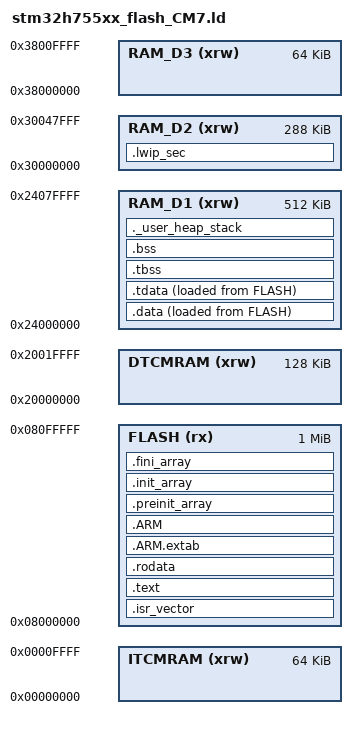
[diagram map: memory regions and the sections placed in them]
/*
******************************************************************************
**
**  File        : LinkerScript.ld
**
**  Abstract    : Linker script for STM32H755 (Cortex-M7)
**                1024Kbytes FLASH and correct RAM mapping for Ethernet
**
**  Target      : STMicroelectronics STM32H755ZIT6
**
******************************************************************************
*/

/* Entry Point */
ENTRY(Reset_Handler)

/* Specify the memory areas */
MEMORY
{
  DTCMRAM (xrw)  : ORIGIN = 0x20000000, LENGTH = 128K
  ITCMRAM (xrw)  : ORIGIN = 0x00000000, LENGTH = 64K
  RAM_D1 (xrw)   : ORIGIN = 0x24000000, LENGTH = 512K  /* AXI SRAM */
  RAM_D2 (xrw)   : ORIGIN = 0x30000000, LENGTH = 288K  /* AHB SRAM (for Ethernet DMA) */
  RAM_D3 (xrw)   : ORIGIN = 0x38000000, LENGTH = 64K   /* AHB SRAM 4 */
  FLASH (rx)     : ORIGIN = 0x08000000, LENGTH = 1024K
}

/* Highest address of the user mode stack */
_estack = 0x20020000;    /* end of DTCMRAM */

/* Generate a link error if heap and stack don't fit into RAM */
_Min_Heap_Size = 0x10000;    /* newlib heap for micro-ROS/newlib runtime */
_Min_Stack_Size = 0x2000;    /* MSP headroom during early boot and faults */

/* Define output sections */
SECTIONS
{
  /* The startup code goes first into FLASH */
  .isr_vector :
  {
    . = ALIGN(4);
    KEEP(*(.isr_vector)) /* Startup code */
    . = ALIGN(4);
  } >FLASH

  /* The program code and other data goes into FLASH */
  .text :
  {
    . = ALIGN(4);
    *(.text)           /* .text sections (code) */
    *(.text*)          /* .text* sections (code) */
    *(.glue_7)         /* glue arm to thumb code */
    *(.glue_7t)        /* glue thumb to arm code */
    *(.eh_frame)

    KEEP (*(.init))
    KEEP (*(.fini))

    . = ALIGN(4);
    _etext = .;        /* define a global symbols at end of code */
  } >FLASH

  /* Constant data goes into FLASH */
  .rodata :
  {
    . = ALIGN(4);
    *(.rodata)         /* .rodata sections (constants, strings, etc.) */
    *(.rodata*)        /* .rodata* sections (constants, strings, etc.) */
    . = ALIGN(4);
  } >FLASH

  .ARM.extab (READONLY) : /* The READONLY keyword is only supported in GCC11 and later, remove it if using GCC10 or earlier. */
  {
    . = ALIGN(4);
    *(.ARM.extab* .gnu.linkonce.armextab.*)
    . = ALIGN(4);
  } >FLASH

  .ARM (READONLY) : /* The READONLY keyword is only supported in GCC11 and later, remove it if using GCC10 or earlier. */
  {
    . = ALIGN(4);
    __exidx_start = .;
    *(.ARM.exidx*)
    __exidx_end = .;
    . = ALIGN(4);
  } >FLASH

  .preinit_array (READONLY) : /* The READONLY keyword is only supported in GCC11 and later, remove it if using GCC10 or earlier. */
  {
    . = ALIGN(4);
    PROVIDE_HIDDEN (__preinit_array_start = .);
    KEEP (*(.preinit_array*))
    PROVIDE_HIDDEN (__preinit_array_end = .);
    . = ALIGN(4);
  } >FLASH

  .init_array (READONLY) : /* The READONLY keyword is only supported in GCC11 and later, remove it if using GCC10 or earlier. */
  {
    . = ALIGN(4);
    PROVIDE_HIDDEN (__init_array_start = .);
    KEEP (*(SORT(.init_array.*)))
    KEEP (*(.init_array*))
    PROVIDE_HIDDEN (__init_array_end = .);
    . = ALIGN(4);
  } >FLASH

  .fini_array (READONLY) : /* The READONLY keyword is only supported in GCC11 and later, remove it if using GCC10 or earlier. */
  {
    . = ALIGN(4);
    PROVIDE_HIDDEN (__fini_array_start = .);
    KEEP (*(SORT(.fini_array.*)))
    KEEP (*(.fini_array*))
    PROVIDE_HIDDEN (__fini_array_end = .);
    . = ALIGN(4);
  } >FLASH

  /* used by the startup to initialize data */
  _sidata = LOADADDR(.data);

  /* Initialized data sections goes into RAM, load LMA copy after code */
  .data :
  {
    . = ALIGN(4);
    _sdata = .;        /* create a global symbol at data start */
    *(.data)           /* .data sections */
    *(.data*)          /* .data* sections */
    . = ALIGN(4);
  } >RAM_D1 AT> FLASH

  /* Initialized TLS data section */
  .tdata : ALIGN(4)
  {
    *(.tdata .tdata.* .gnu.linkonce.td.*)
    . = ALIGN(4);
    _edata = .;        /* define a global symbol at data end */
    PROVIDE(__data_end = .);
    PROVIDE(__tdata_end = .);
  } >RAM_D1 AT> FLASH

  PROVIDE( __tdata_start = ADDR(.tdata) );
  PROVIDE( __tdata_size = __tdata_end - __tdata_start );

  PROVIDE( __data_start = ADDR(.data) );
  PROVIDE( __data_size = __data_end - __data_start );

  PROVIDE( __tdata_source = LOADADDR(.tdata) );
  PROVIDE( __tdata_source_end = LOADADDR(.tdata) + SIZEOF(.tdata) );
  PROVIDE( __tdata_source_size = __tdata_source_end - __tdata_source );

  PROVIDE( __data_source = LOADADDR(.data) );
  PROVIDE( __data_source_end = __tdata_source_end );
  PROVIDE( __data_source_size = __data_source_end - __data_source );

  /* Uninitialized TLS data section */
  .tbss (NOLOAD) : ALIGN(4)
  {
    _sbss = .;         /* define a global symbol at bss start */
    __bss_start__ = _sbss;
    *(.tbss .tbss.*)
    . = ALIGN(4);
    PROVIDE( __tbss_end = . );
  } >RAM_D1

  PROVIDE( __tbss_start = ADDR(.tbss) );
  PROVIDE( __tbss_size = __tbss_end - __tbss_start );
  PROVIDE( __tbss_offset = ADDR(.tbss) - ADDR(.tdata) );

  PROVIDE( __tls_base = __tdata_start );
  PROVIDE( __tls_end = __tbss_end );
  PROVIDE( __tls_size = __tls_end - __tls_base );
  PROVIDE( __tls_align = MAX(ALIGNOF(.tdata), ALIGNOF(.tbss)) );
  PROVIDE( __tls_size_align = (__tls_size + __tls_align - 1) & ~(__tls_align - 1) );
  PROVIDE( __arm32_tls_tcb_offset = MAX(8, __tls_align) );
  PROVIDE( __arm64_tls_tcb_offset = MAX(16, __tls_align) );

  /* Uninitialized data section */
  .bss (NOLOAD) : ALIGN(4)
  {
    *(.bss)
    *(.bss*)
    *(COMMON)
    . = ALIGN(4);
    _ebss = .;         /* define a global symbol at bss end */
    __bss_end__ = _ebss;
    PROVIDE( __bss_end = .);
  } >RAM_D1

  PROVIDE( __non_tls_bss_start = ADDR(.bss) );
  PROVIDE( __bss_start = __tbss_start );
  PROVIDE( __bss_size = __bss_end - __bss_start );

  /* ========================================================================== */
  /* CRITICAL: Ethernet DMA Descriptors and Buffers in D2 SRAM (Non-Cacheable) */
  /* This MUST be in RAM_D2 (0x30000000) for proper MPU configuration          */
  /* ========================================================================== */
  .lwip_sec (NOLOAD) :
  {
    . = ABSOLUTE(0x30000000);
    *(.RxDecripSection)       /* Ethernet RX DMA Descriptors */

    . = ABSOLUTE(0x30000080);
    *(.TxDecripSection)       /* Ethernet TX DMA Descriptors */

    . = ABSOLUTE(0x30000200);
    *(.RxArraySection)        /* Ethernet RX Buffers */
    *(.Rx_PoolSection)        /* LwIP RX Pool Memory - FIX: Added missing section */

    . = ALIGN(4); /* Continue after RxArraySection/Rx_PoolSection */
    *(.Heap_Mem_Section)      /* LwIP Heap Memory */
  } >RAM_D2

  /* User_heap_stack section, used to check that there is enough RAM left */
  ._user_heap_stack (NOLOAD) :
  {
    . = ALIGN(8);
    PROVIDE ( end = . );
    PROVIDE ( _end = . );
    . = . + _Min_Heap_Size;
    . = . + _Min_Stack_Size;
    . = ALIGN(8);
  } >RAM_D1

  /* Remove information from the standard libraries */
  /DISCARD/ :
  {
    libc.a ( * )
    libm.a ( * )
    libgcc.a ( * )
  }

  .ARM.attributes 0 : { *(.ARM.attributes) }
}
